# N32G401 register map
Vendor: Nationstech Ltd.; File version: 1.0
Registers are 32-bit, read-write, reset 0x0 unless marked. A register's access mark holds for its fields unless they carry their own. Offsets are from the block's base; lines under a group give offsets from that group; [hi:lo] are bit positions; {n}, {i} and the like mark numbered series; 'fields as' and 'values as' point back to an identical list; <NAME> marks a mode.

## Memory map
0x40000000 TIM2 size 0x400 — General purpose timer
0x40000400 TIM3 size 0x400 — General purpose timer
0x40000800 TIM4 size 0x400 — General purpose timer
0x40000C00 TIM5 size 0x400 — General purpose timer
0x40001000 TIM6 size 0x400 — Basic timer
0x40002400 COMP size 0x400 — comparator
0x40002800 RTC size 0x400 — Real time clock
0x40002C00 WWDG size 0x400 — window watchdog
0x40003000 IWDG size 0x400 — Independent watchdog
0x40004400 USART2 size 0x400
0x40004C00 LPTIM size 0x400 — Low power timer control
0x40005400 I2C1 size 0x400 — Inter integrated circuit
0x40005800 I2C2 size 0x400
0x40007000 PWR size 0x400 — Power control
0x40010000 AFIO size 0x400 — Alternate function I/O
0x40010400 EXTI size 0x20 — external interrupt/event controller
0x40010800 BEEPER size 0x400 — Beeper unit
0x40012C00 TIM1 size 0x400 — Advanced timer
0x40013000 SPI1 size 0x400 — Serial peripheral interface
0x40013400 TIM8 size 0x400 — Advanced timer
0x40013800 USART1 size 0x400 — Universal synchronous asynchronous receiver transmitter
0x40013C00 SPI2 size 0x400 — Serial peripheral interface
0x40015000 UART3 size 0x400 — Universal asynchronous receiver transmitter
0x40015400 UART4 size 0x400
0x40020000 DMA size 0x400 — Direct memory access controller
0x40020800 ADC size 0x400 — analog to digital converter
0x40021000 RCC size 0x40 — Reset and clock control
0x40022000 FLASH size 0x38 — interal FLASH controller
0x40023000 CRC size 0x20 — cyclic redundancy check
0x40023400 GPIOA size 0x400 — General purpose I/O
0x40023800 GPIOB size 0x400
0x40023C00 GPIOC size 0x400
0x40024000 GPIOD size 0x400
0xE0042000 DBG size 0x400 — debug support for MCU

## Interrupts
0 WWDG — WWDG interrupt
1 PVD (PWR) — PVD through EXTI line detection interrupt
2 RTC_TAMPER_STAMP (RTC) — RTC Tamper interrupt or Timestamp through EXTI line 18
3 RTC_WKUP (RTC) — RTC wakeup timer through EXTI line 19 interrupt
4 FLASH — FLASH interrupt
5 RCC — RCC interrupt
6 EXTI0 (EXTI) — EXTI0 interrupt
7 EXTI1 (EXTI) — EXTI1 interrupt
8 EXTI2 (EXTI) — EXTI2 interrupt
9 EXTI3 (EXTI) — EXTI3 interrupt
10 EXTI4 (EXTI) — EXTI4 interrupt
{n+10} DMA_Channel{n} (DMA) (n=1..8) — DMA channel{n} global interrupt
19 ADC — ADC global interrupt
21 COMP — COMP1/2 global interrupt through EXTI line 21/22/23
22 EXTI9_5 (EXTI) — EXTI5/6/7/8/9 interrupt
23 TIM1_BRK (TIM1) — TIM1 Break interrupt
24 TIM1_UP (TIM1) — TIM1 Update interrupt
25 TIM1_TRG_COM (TIM1) — TIM1 Trigger and Commutation interrupts
26 TIM1_CC (TIM1) — TIM1 Capture Compare interrupt
27 TIM2 — TIM2 global interrupt
28 TIM3 — TIM3 global interrupt
29 TIM4 — TIM4 global interrupt
30 I2C1_EV (I2C1) — I2C1 Event interrupt
31 I2C1_ER (I2C1) — I2C1 Error interrupt
32 I2C2_EV (I2C2) — I2C2 Event interrupt
33 I2C2_ER (I2C2) — I2C2 Error interrupt
34 SPI1 — SPI1 global interrupt
35 SPI2 — SPI2 global interrupt
36 USART1 — USART1 global interrupt
37 USART2 — USART2 global interrupt
38 UART3 — UART3 global interrupt
39 EXTI15_10 (EXTI) — EXTI10/11/12/13/14/15 interrupt
40 RTC_Alarm (RTC) — RTC Alarm through EXTI Line 17 Interrupt
41 LPTIM_WKUP (LPTIM) — LPTIMER wakeup interrupt through EXTI line 20
42 TIM8_BRK (TIM8) — TIM8 Break interrupt
43 TIM8_UP (TIM8) — TIM8 Update interrupt
44 TIM8_TRG_COM (TIM8) — TIM8 Trigger and Commutation interrupts
45 TIM8_CC (TIM8) — TIM8 Capture Compare interrupt
46 UART4 — UART4 global interrupt
47 TIM5 — TIM5 global interrupt
48 TIM6 — TIM6 global interrupt

## ADC — analog to digital converter
Base 0x40020800
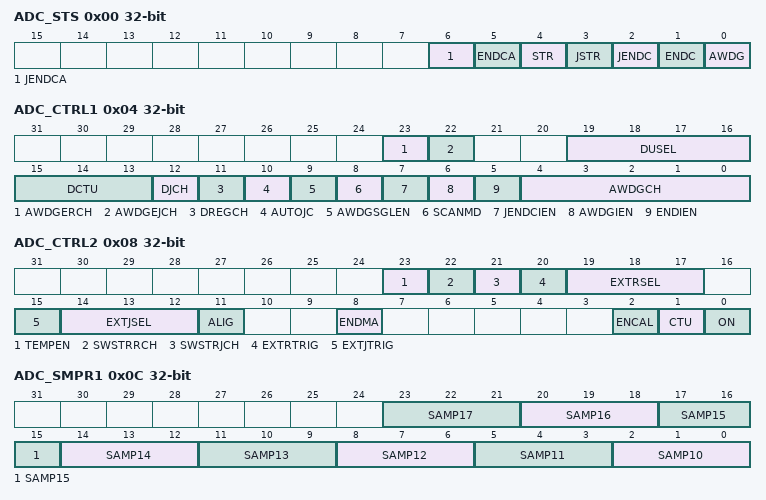
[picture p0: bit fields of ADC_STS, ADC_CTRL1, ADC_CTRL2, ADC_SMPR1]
0x00 ADC_STS
  [6] JENDCA, [5] ENDCA, [4] STR, [3] JSTR, [2] JENDC, [1] ENDC, [0] AWDG
0x04 ADC_CTRL1
  [23] AWDGERCH, [22] AWDGEJCH, [19:16] DUSEL, [15:13] DCTU, [12] DJCH, [11] DREGCH, [10] AUTOJC, [9] AWDGSGLEN, [8] SCANMD, [7] JENDCIEN, [6] AWDGIEN, [5] ENDIEN, [4:0] AWDGCH
0x08 ADC_CTRL2
  [23] TEMPEN, [22] SWSTRRCH, [21] SWSTRJCH, [20] EXTRTRIG, [19:17] EXTRSEL, [15] EXTJTRIG, [14:12] EXTJSEL, [11] ALIG, [8] ENDMA, [2] ENCAL, [1] CTU, [0] ON
0x0C ADC_SMPR1
  [3n-28:3n-30] SAMP{n} (n=10..17)
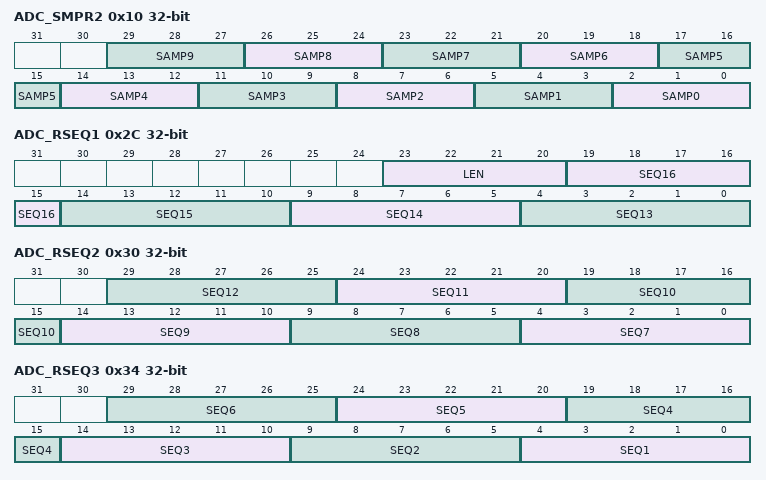
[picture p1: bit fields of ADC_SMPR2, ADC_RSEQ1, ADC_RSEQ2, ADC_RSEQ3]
0x10 ADC_SMPR2
  [3n+2:3n] SAMP{n} (n=0..9)
{0x10+4i} ADC_JOFFSET{i} (i=1..4)
  [11:0] OFFSETJCH{i}
0x24 ADC_WDGHIGH
  [15:0] HTH
0x28 ADC_WDGLOW
  [15:0] LTH
0x2C ADC_RSEQ1
  [23:20] LEN, [5n-61:5n-65] SEQ{n} (n=13..16)
0x30 ADC_RSEQ2
  [5n-31:5n-35] SEQ{n} (n=7..12)
0x34 ADC_RSEQ3
  [5n-1:5n-5] SEQ{n} (n=1..6)
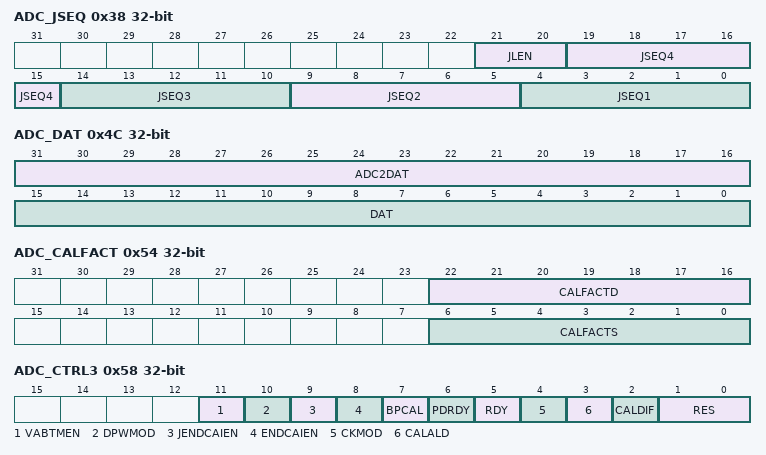
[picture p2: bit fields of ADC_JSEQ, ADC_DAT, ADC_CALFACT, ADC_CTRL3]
0x38 ADC_JSEQ
  [21:20] JLEN, [5n-1:5n-5] JSEQ{n} (n=1..4)
{0x38+4i} ADC_JDAT{i} (i=1..4)
  [15:0] JDAT{i}
0x4C ADC_DAT (reset mask 0xFFFF)
  [31:16] ADC2DAT, [15:0] DAT
0x50 ADC_DIFSEL
  [18:1] DIFSEL
0x54 ADC_CALFACT
  [22:16] CALFACTD, [6:0] CALFACTS
0x58 ADC_CTRL3
  [11] VABTMEN, [10] DPWMOD, [9] JENDCAIEN, [8] ENDCAIEN, [7] BPCAL, [6] PDRDY, [5] RDY, [4] CKMOD, [3] CALALD, [2] CALDIF, [1:0] RES
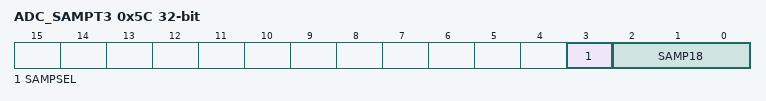
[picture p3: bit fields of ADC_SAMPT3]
0x5C ADC_SAMPT3
  [3] SAMPSEL, [2:0] SAMP18
